# RN821X_RN721X_SOC_C register map
File version: v1.0.6
CPU: CM0 r0p0, little endian, no MPU, no FPU, 3 interrupt priority bits
Registers are 32-bit, read-write, reset 0x0 unless marked. A register's access mark holds for its fields unless they carry their own. Offsets are from the block's base; [hi:lo] are bit positions; {n}, {i} and the like mark numbered series.

## KBI — key detection
Base 0x40028000
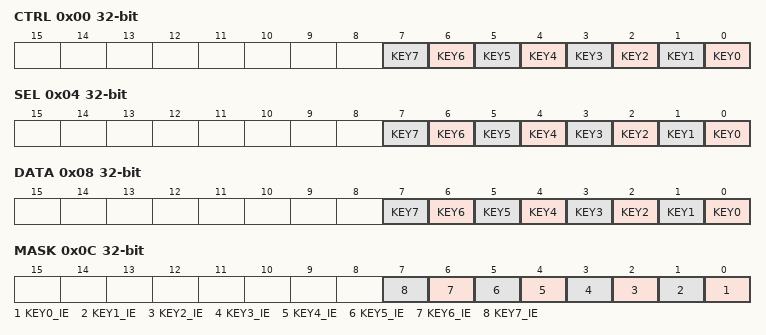
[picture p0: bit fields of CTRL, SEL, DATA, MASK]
0x00 CTRL — KBI control register
  [n] KEY{n} (n=0..7) — KBI KEY{n} enable/disable bit
    1=EN (KBI KEY{n} enable); 0=DIS (KBI KEY{n} disable)
0x04 SEL — KBI trigger mode select register
  [all] fields
    0=PE (KBI select posedge sampling); 1=NE (KBI select negedge sampling)
  [n] KEY{n} (n=0..7) — KBI KEY{n} posedge/negedge selection bit
0x08 DATA — KBI data register
  [all] fields
    1=PD (KEY pressed); 0=NUL (KEY not be pressed)
  [n] KEY{n} write-1-clears (n=0..7) — KBI KEY{n} data bit indicate key pressed or not
0x0C MASK — KBI interrupt mask register
  [n] KEY{n}_IE (n=0..7) — KBI KEY{n} interrupt enable/disable bit

## LCD — liquid crystal display
Base 0x40048000
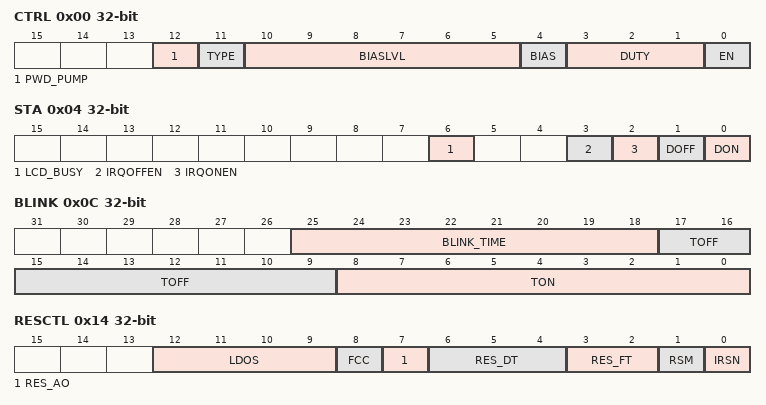
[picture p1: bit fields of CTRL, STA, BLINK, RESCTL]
0x00 CTRL — LCD control register
  [12] PWD_PUMP — LCD PUMP disable/enable bit
    0=EN (LCD PUMP enable); 1=DIS (LCD PUMP disable)
  [11] TYPE — LCD drive type selection bit
    0=A (select LCD drive type A as LCD drive type); 1=B (select LCD drive type B as LCD drive type)
  [10:5] BIASLVL — LCD voltage Bias configuration bits
  [4] BIAS — LCD voltage bias control bit
    0=1_3 (select LCD bias as 1/3 voltage bias); 1=1_4 (select LCD bias as 1/3 voltage bias)
  [3:1] DUTY — LCD duty cycle selection bits
    0=STA (static output (COM0)); 1=1_2 (duty cycle = 1/2 (COM0~1)); 2=1_3 (duty cycle = 1/3 (COM0~2)); 3=1_4 (duty cycle = 1/4 (COM0~3)); 4=1_6 (duty cycle = 1/6 (COM0~5)); 5=1_8 (duty cycle = 1/8 (COM0~7))
  [0] EN — LCD module enable/disable bit
0x04 STA — LCD status register
  [6] LCD_BUSY ro — LCD Busy Bit
  [3] IRQOFFEN — Display Off IRQ Enble Bit
  [2] IRQONEN — Display On IRQ Enble Bit
  [1] DOFF write-1-clears — Display Off Pending Bit
    0=NUL (LCD Display Off did not occured); 1=OCC (LCD Display Off occured)
  [0] DON write-1-clears — Display On Pending Bit
    0=NUL (LCD Display On did not occured); 1=OCC (LCD Display On occured)
0x08 CLKDIV — LCD clock divisor register
  [7:0] CLKDIV — LCD clock divisor configuration bits
0x0C BLINK — LCD blink control register
  [25:18] BLINK_TIME — blink duration configuration bits
  [17:9] TOFF — blink off duration configuration bits
  [8:0] TON — blink on duration configuration bits
0x10 PS — LCD PUMP set-up duration register
  [15:0] PS — PUMP Set-up duration configuration bits,duration equal to 30.5us * (4 + PS)
0x14 RESCTL — LCD internal resistance control register
  [12:9] LDOS — LDO output level selection bits
    0=2P7 (select LDO 2.7 v as output level); 1=2P76 (select LDO 2.76v as output level); 2=2P82 (select LDO 2.82v as output level); 3=2P88 (select LDO 2.88v as output level); 4=2P94 (select LDO 2.94v as output level); 5=3P0 (select LDO 3.0v as output level); 6=3P06 (select LDO 3.06v as output level); 7=3P12 (select LDO 3.12v as output level); 8=3P18 (select LDO 3.18v as output level); 9=3P24 (select LDO 3.24v as output level); 10=3P3 (select LDO 3.3v as output level); 11=3P36 (select LDO 3.36v as output level); 12=3P42 (select LDO 3.42v as output level); 13=3P48 (select LDO 3.48v as output level); 14=3P54 (select LDO 3.54v as output level); 15=3P6 (select LDO 3.6v as output level)
  [8] FCC — fast charging control bit
    0=OFF (Turn off fast charging function); 1=ON (Turn on fast charging function)
  [7] RES_AO — resistance divider mode driver control switch
    0=ON (resistors is driven time-sharing); 1=OFF (resistors is always driven)
  [6:4] RES_DT — resistance divider mode driving time (one screen refresh cycle) configuration bits
  [3:2] RES_FT — resistance divider mode driving times(one screen refresh cycle) configuration bits
    0=driving once per cycle; 1=driving 2 times per cycle; 2=driving 3 times per cycle; 3=driving 4 times per cycle
  [1] RSM — internal resistance divider mode signal selection bit
    0=SO (20k resistor time sharing connected, 200k resistor short circuited); 1=SL (time sharing switching between 20k resistor and 200k resistor)
  [0] IRSN — resistance divider mode selection bit
    0=IR (select internal resistance divider mode)
{0x20+i} BUF{i} 8-bit (i=0..31) — Data register of SEG({i}) COM[7:0]
  [7:0] BUF{i} — Data bits of SEG({i}) COM[7:0]
